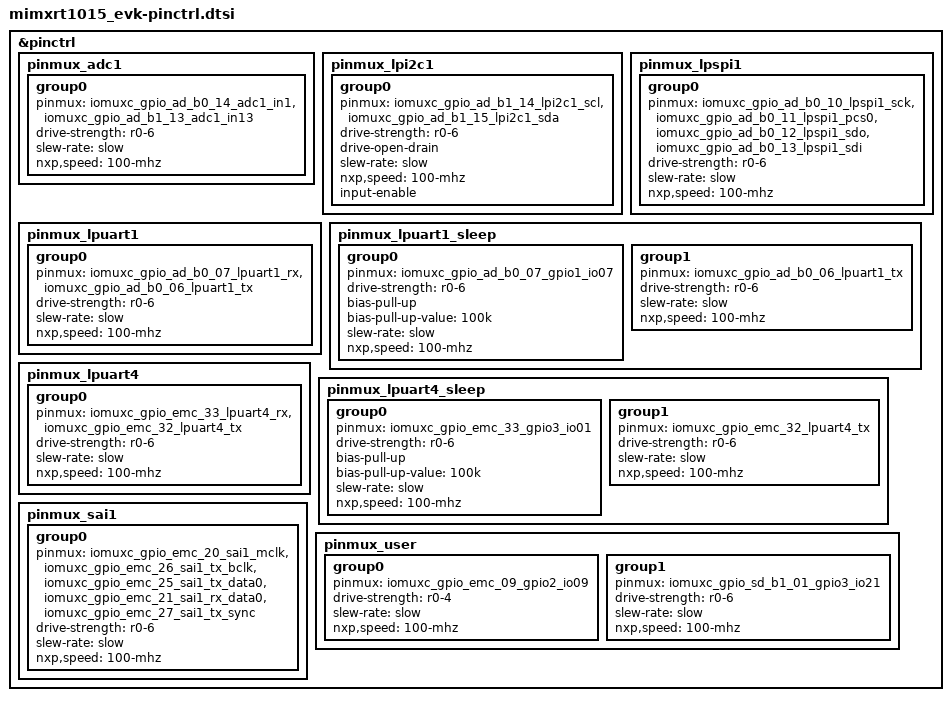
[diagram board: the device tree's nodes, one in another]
/*
 * Copyright (c) 2022, NXP
 * SPDX-License-Identifier: Apache-2.0
 *
 * Note: File generated by rt_cfg_utils.py
 * from mimxrt1015_evk.mex
 */

#include <nxp/nxp_imx/rt/mimxrt1015daf5a-pinctrl.dtsi>

&pinctrl {
	/* adc1 inputs 1 and 13 */
	pinmux_adc1: pinmux_adc1 {
		group0 {
			pinmux = <&iomuxc_gpio_ad_b0_14_adc1_in1>,
				<&iomuxc_gpio_ad_b1_13_adc1_in13>;
			drive-strength = "r0-6";
			slew-rate = "slow";
			nxp,speed = "100-mhz";
		};
	};

	pinmux_lpi2c1: pinmux_lpi2c1 {
		group0 {
			pinmux = <&iomuxc_gpio_ad_b1_14_lpi2c1_scl>,
				<&iomuxc_gpio_ad_b1_15_lpi2c1_sda>;
			drive-strength = "r0-6";
			drive-open-drain;
			slew-rate = "slow";
			nxp,speed = "100-mhz";
			input-enable;
		};
	};

	pinmux_lpspi1: pinmux_lpspi1 {
		group0 {
			pinmux = <&iomuxc_gpio_ad_b0_10_lpspi1_sck>,
				<&iomuxc_gpio_ad_b0_11_lpspi1_pcs0>,
				<&iomuxc_gpio_ad_b0_12_lpspi1_sdo>,
				<&iomuxc_gpio_ad_b0_13_lpspi1_sdi>;
			drive-strength = "r0-6";
			slew-rate = "slow";
			nxp,speed = "100-mhz";
		};
	};

	pinmux_lpuart1: pinmux_lpuart1 {
		group0 {
			pinmux = <&iomuxc_gpio_ad_b0_07_lpuart1_rx>,
				<&iomuxc_gpio_ad_b0_06_lpuart1_tx>;
			drive-strength = "r0-6";
			slew-rate = "slow";
			nxp,speed = "100-mhz";
		};
	};

	pinmux_lpuart1_sleep: pinmux_lpuart1_sleep {
		group0 {
			pinmux = <&iomuxc_gpio_ad_b0_07_gpio1_io07>;
			drive-strength = "r0-6";
			bias-pull-up;
			bias-pull-up-value = "100k";
			slew-rate = "slow";
			nxp,speed = "100-mhz";
		};
		group1 {
			pinmux = <&iomuxc_gpio_ad_b0_06_lpuart1_tx>;
			drive-strength = "r0-6";
			slew-rate = "slow";
			nxp,speed = "100-mhz";
		};
	};

	pinmux_lpuart4: pinmux_lpuart4 {
		group0 {
			pinmux = <&iomuxc_gpio_emc_33_lpuart4_rx>,
				<&iomuxc_gpio_emc_32_lpuart4_tx>;
			drive-strength = "r0-6";
			slew-rate = "slow";
			nxp,speed = "100-mhz";
		};
	};

	pinmux_lpuart4_sleep: pinmux_lpuart4_sleep {
		group0 {
			pinmux = <&iomuxc_gpio_emc_33_gpio3_io01>;
			drive-strength = "r0-6";
			bias-pull-up;
			bias-pull-up-value = "100k";
			slew-rate = "slow";
			nxp,speed = "100-mhz";
		};
		group1 {
			pinmux = <&iomuxc_gpio_emc_32_lpuart4_tx>;
			drive-strength = "r0-6";
			slew-rate = "slow";
			nxp,speed = "100-mhz";
		};
	};

	pinmux_sai1: pinmux_sai1 {
		group0 {
			pinmux = <&iomuxc_gpio_emc_20_sai1_mclk>,
				<&iomuxc_gpio_emc_26_sai1_tx_bclk>,
				<&iomuxc_gpio_emc_25_sai1_tx_data0>,
				<&iomuxc_gpio_emc_21_sai1_rx_data0>,
				<&iomuxc_gpio_emc_27_sai1_tx_sync>;
			drive-strength = "r0-6";
			slew-rate = "slow";
			nxp,speed = "100-mhz";
		};
	};

	/* user led and board SW4 */
	pinmux_user: pinmux_user {
		group0 {
			pinmux = <&iomuxc_gpio_emc_09_gpio2_io09>;
			drive-strength = "r0-4";
			slew-rate = "slow";
			nxp,speed = "100-mhz";
		};
		group1 {
			pinmux = <&iomuxc_gpio_sd_b1_01_gpio3_io21>;
			drive-strength = "r0-6";
			slew-rate = "slow";
			nxp,speed = "100-mhz";
		};
	};

};

